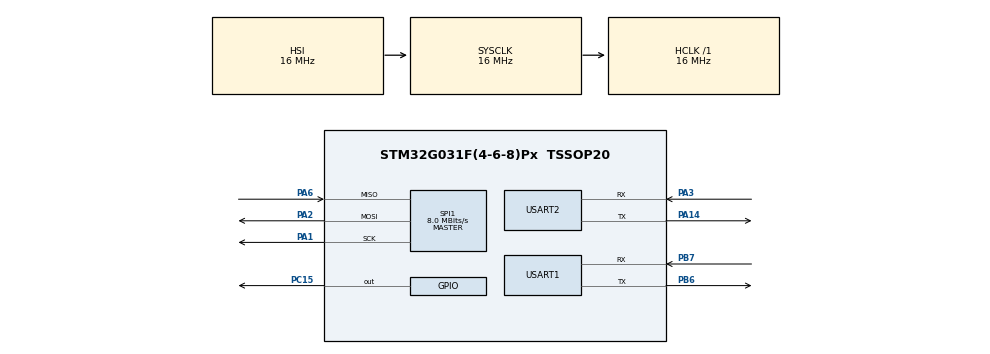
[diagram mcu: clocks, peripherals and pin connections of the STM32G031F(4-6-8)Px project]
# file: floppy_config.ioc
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Mcu.Family=STM32G0
Mcu.Name=STM32G031F(4-6-8)Px
Mcu.Package=TSSOP20
NVIC.SPI1_IRQn=true\:0\:0\:false\:false\:true\:true\:true\:true
PA1.Mode=Full_Duplex_Master
PA1.Signal=SPI1_SCK
PA14-BOOT0.Mode=Asynchronous
PA14-BOOT0.Signal=USART2_TX
PA14-BOOT0__PA15.StandardMode=true
PA2.Mode=Full_Duplex_Master
PA2.Signal=SPI1_MOSI
PA3.Mode=Asynchronous
PA3.Signal=USART2_RX
PA6.Mode=Full_Duplex_Master
PA6.Signal=SPI1_MISO
PB0__PB1__PB2__PA8.StandardMode=true
PB3__PB4__PB5__PB6.StandardMode=true
PB6.Mode=Asynchronous
PB6.Signal=USART1_TX
PB7.Mode=Asynchronous
PB7.Signal=USART1_RX
PB7__PB8.StandardMode=true
PC14-OSC32_IN\ (PC14)__PB9.StandardMode=true
PC15-OSC32_OUT\ (PC15).Signal=GPIO_Output
ProjectManager.HeapSize=0x200
ProjectManager.StackSize=0x400
ProjectManager.TargetToolchain=EWARM V8.50
RCC.AHBFreq_Value=16000000
RCC.CortexFreq_Value=16000000
RCC.EXTERNAL_CLOCK_VALUE=12288000
RCC.HCLKFreq_Value=16000000
RCC.HSE_VALUE=8000000
RCC.HSI_VALUE=16000000
RCC.SYSCLKFreq_VALUE=16000000
RCC.VCOOutputFreq_Value=128000000
SPI1.CalculateBaudRate=8.0 MBits/s
SPI1.Direction=SPI_DIRECTION_2LINES
SPI1.Mode=SPI_MODE_MASTER
SPI1.VirtualType=VM_MASTER
USART1.VirtualMode-Asynchronous=VM_ASYNC
USART2.VirtualMode-Asynchronous=VM_ASYNC
board=custom

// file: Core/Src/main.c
/* USER CODE BEGIN Header */
/**
  ******************************************************************************
  * @file           : main.c
  * @brief          : Main program body
  ******************************************************************************
  * @attention
  *
  * Copyright (c) 2025 STMicroelectronics.
  * All rights reserved.
  *
  * This software is licensed under terms that can be found in the LICENSE file
  * in the root directory of this software component.
  * If no LICENSE file comes with this software, it is provided AS-IS.
  *
  ******************************************************************************
  */
/* USER CODE END Header */
#include "main.h"
#include "spi.h"
#include "usart.h"
#include "gpio.h"

void SystemClock_Config(void);

int main(void)
{

  /* MCU Configuration--------------------------------------------------------*/

  /* Reset of all peripherals, Initializes the Flash interface and the Systick. */
  HAL_Init();

  /* Configure the system clock */
  SystemClock_Config();

  /* Initialize all configured peripherals */
  MX_GPIO_Init();
  MX_SPI1_Init();
  MX_USART1_UART_Init();
  MX_USART2_UART_Init();

  /* Infinite loop */
  while (1)
  {

    /* USER CODE BEGIN 3 */
    HAL_GPIO_TogglePin(GPIOC, GPIO_PIN_15); // pin PC15
    HAL_Delay(850);
  }
  /* USER CODE END 3 */
}

void SystemClock_Config(void)
{
  RCC_OscInitTypeDef RCC_OscInitStruct = {0};
  RCC_ClkInitTypeDef RCC_ClkInitStruct = {0};

  /** Configure the main internal regulator output voltage
  */
  HAL_PWREx_ControlVoltageScaling(PWR_REGULATOR_VOLTAGE_SCALE1);

  /** Initializes the RCC Oscillators according to the specified parameters
  * in the RCC_OscInitTypeDef structure.
  */
  RCC_OscInitStruct.OscillatorType = RCC_OSCILLATORTYPE_HSI;
  RCC_OscInitStruct.HSIState = RCC_HSI_ON;
  RCC_OscInitStruct.HSIDiv = RCC_HSI_DIV1;
  RCC_OscInitStruct.HSICalibrationValue = RCC_HSICALIBRATION_DEFAULT;
  RCC_OscInitStruct.PLL.PLLState = RCC_PLL_NONE;
  if (HAL_RCC_OscConfig(&RCC_OscInitStruct) != HAL_OK)
  {
    Error_Handler();
  }

  /** Initializes the CPU, AHB and APB buses clocks
  */
  RCC_ClkInitStruct.ClockType = RCC_CLOCKTYPE_HCLK|RCC_CLOCKTYPE_SYSCLK
                              |RCC_CLOCKTYPE_PCLK1;
  RCC_ClkInitStruct.SYSCLKSource = RCC_SYSCLKSOURCE_HSI;
  RCC_ClkInitStruct.AHBCLKDivider = RCC_SYSCLK_DIV1;
  RCC_ClkInitStruct.APB1CLKDivider = RCC_HCLK_DIV1;

  if (HAL_RCC_ClockConfig(&RCC_ClkInitStruct, FLASH_LATENCY_0) != HAL_OK)
  {
    Error_Handler();
  }
}

void Error_Handler(void)
{
  __disable_irq();
  while (1)
  {
  }
}
